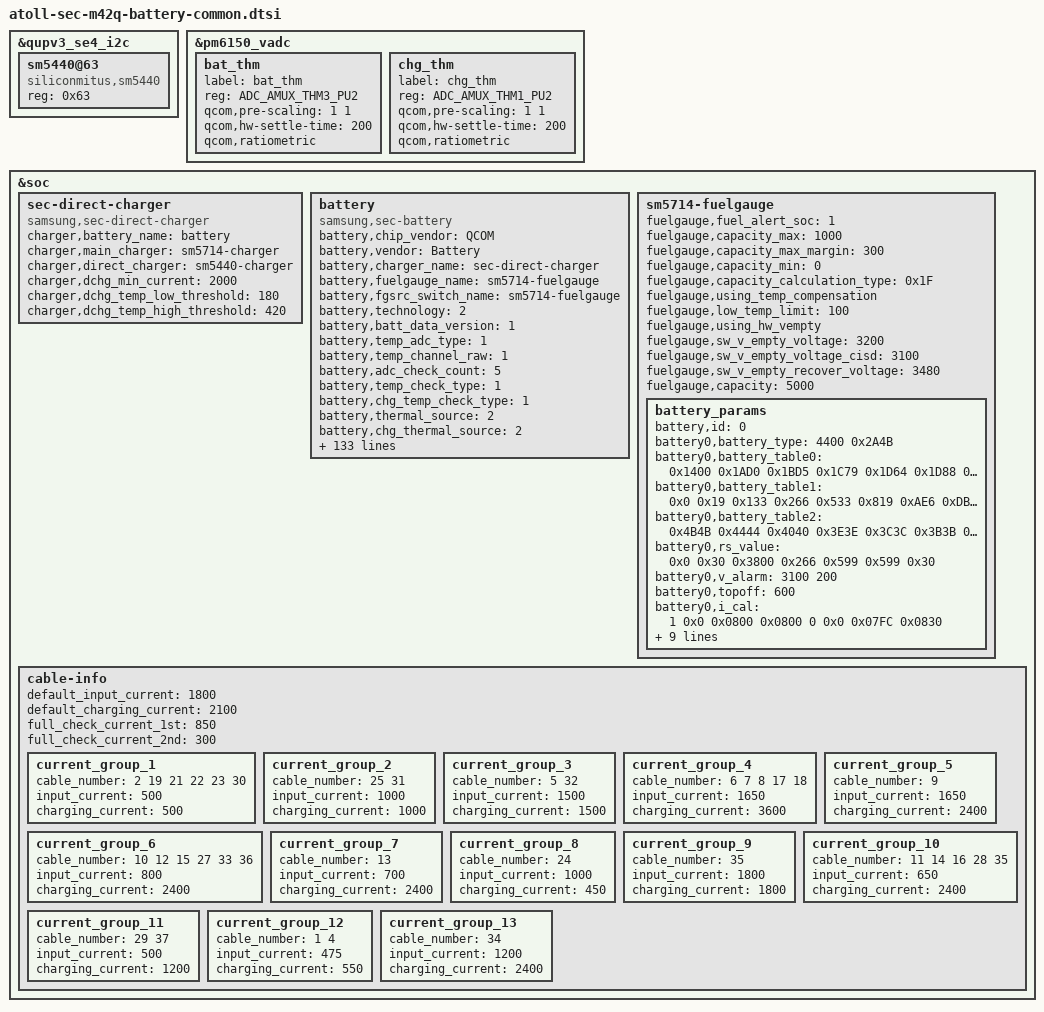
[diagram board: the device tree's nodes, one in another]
/* Copyright (c) 2016-2019, The Linux Foundation. All rights reserved.
 *
 * This program is free software; you can redistribute it and/or modify
 * it under the terms of the GNU General Public License version 2 and
 * only version 2 as published by the Free Software Foundation.
 *
 * This program is distributed in the hope that it will be useful,
 * but WITHOUT ANY WARRANTY; without even the implied warranty of
 * MERCHANTABILITY or FITNESS FOR A PARTICULAR PURPOSE.  See the
 * GNU General Public License for more details.
 */

#include <dt-bindings/iio/qcom,spmi-vadc.h>

&qupv3_se4_i2c {
	status = "okay";
	sm5440@63{
		status = "okay";
		compatible = "siliconmitus,sm5440";
		reg = <0x63>;
		pinctrl-names = "default";

	};
};

&pm6150_vadc {
	bat_thm { /* AMUX_3 */
		label = "bat_thm";
		reg = <ADC_AMUX_THM3_PU2>;
		qcom,pre-scaling = <1 1>;
		qcom,hw-settle-time = <200>;
		qcom,ratiometric;
	};
	chg_thm { /* AMUX_1 */
		label = "chg_thm";
		reg = <ADC_AMUX_THM1_PU2>;
		qcom,pre-scaling = <1 1>;
		qcom,hw-settle-time = <200>;
		qcom,ratiometric;
	};
};

&soc {

	sec-direct-charger {
		status = "okay";
		compatible = "samsung,sec-direct-charger";

		charger,battery_name = "battery";
		charger,main_charger = "sm5714-charger";
		charger,direct_charger = "sm5440-charger";

		charger,dchg_min_current = <2000>;
		charger,dchg_temp_low_threshold = <180>;
		charger,dchg_temp_high_threshold = <420>;

	};

	battery {
		pinctrl-names = "default";

		battery,chip_vendor = "QCOM";
		status = "okay";
		compatible = "samsung,sec-battery";
		battery,vendor = "Battery";
		battery,charger_name = "sec-direct-charger";
		battery,fuelgauge_name = "sm5714-fuelgauge";
		battery,fgsrc_switch_name = "sm5714-fuelgauge"; /* Fuelgauge voltage source */
		battery,technology = <2>; /* POWER_SUPPLY_TECHNOLOGY_LION */

		battery,batt_data_version = <1>;

		battery,temp_adc_type = <1>; /* SEC_BATTERY_ADC_TYPE_AP */
		battery,temp_channel_raw = <1>; /* ADC_TEMP_CHANNEL_RAW */
		battery,adc_check_count = <5>;
		battery,temp_check_type = <1>;
		battery,chg_temp_check_type = <1>;

		battery,thermal_source = <2>; /* SEC_BATTERY_THERMAL_SOURCE_ADC */
		battery,chg_thermal_source = <2>; /* SEC_BATTERY_THERMAL_SOURCE_ADC */

		battery,temp_table_adc = <2453 2872 3359 3926 4589 5313 6237
					7287 8486 9775 11135 12659 14316
					15939 17586 19166 20643 21991 23237 24313 25235 26017 26642>;
		battery,temp_table_data = <900 850 800 750 700 650 600 550 500 450
					400 350 300 250 200 150 100 50 0 (-50) (-100) (-150) (-200)>;
		battery,chg_temp_table_adc =  <1820 2174 2587 3056 3614 4233 5023
					5950 7018 8183 9450 10902 12530
					14160 15870 17555 19181 20710 22144 23412 24537 25505 26295>;
		battery,chg_temp_table_data = <900 850 800 750 700 650 600 550 500 450
			400 350 300 250 200 150 100 50 0 (-50) (-100) (-150) (-200)>;

		battery,polling_time = <10 30 30 30 3600>;

		battery,cable_check_type = <4>; /* SEC_BATTERY_CABLE_CHECK_PSY */
		battery,cable_source_type = <1>;
		battery,polling_type = <1>; /* SEC_BATTERY_MONITOR_ALARM */
		battery,monitor_initial_count = <0>;

		battery,battery_check_type = <0>; /* SEC_BATTERY_CHECK_NONE */

		battery,ovp_uvlo_check_type = <3>; /* SEC_BATTERY_OVP_UVLO_CHGPOLLING */

		battery,temp_check_count = <1>;

		battery,overheatlimit_threshold = <700>;
		battery,overheatlimit_recovery = <680>;
		battery,wire_warm_overheat_thresh = <500>;
		battery,wire_normal_warm_thresh = <420>;
		battery,wire_cool1_normal_thresh = <180>;
		battery,wire_cool2_cool1_thresh = <150>;
		battery,wire_cool3_cool2_thresh = <50>;
		battery,wire_cold_cool3_thresh = <0>;

		battery,wire_warm_current = <2093>;	/* 0.36C */
		battery,wire_cool1_current = <3600>;	/* 0.61C */
		battery,wire_cool2_current = <1390>;	/* 0.24C */
		battery,wire_cool3_current = <578>;	/* 0.1C */

		battery,low_temp_topoff = <300>;
		battery,high_temp_topoff = <300>;
		battery,low_temp_float = <4380>;
		battery,high_temp_float = <4150>;

		battery,full_check_type = <7>; /* SEC_BATTERY_FULLCHARGED_CHGPSY */
		battery,full_check_type_2nd = <7>; /* SEC_BATTERY_FULLCHARGED_CHGPSY */
		battery,full_check_count = <1>;
		battery,chg_gpio_full_check = <0>;

		battery,chg_high_temp = <500>;
		battery,chg_high_temp_recovery = <480>;
		battery,chg_input_limit_current = <1000>;
		battery,chg_charging_limit_current = <1400>;

		battery,wpc_temp_control_source = <1>;
		battery,wpc_high_temp = <380>;
		battery,wpc_high_temp_recovery = <360>;
		battery,wpc_input_limit_current = <600>;
		battery,wpc_charging_limit_current = <1000>;
		battery,wpc_temp_lcd_on_control_source = <1>;
		battery,wpc_lcd_on_high_temp = <380>;
		battery,wpc_lcd_on_high_temp_rec = <360>;
		battery,wpc_lcd_on_input_limit_current = <450>;

		battery,wpc_store_high_temp = <360>;
		battery,wpc_store_high_temp_recovery = <340>;
		battery,wpc_store_charging_limit_current = <400>;
		battery,wpc_store_lcd_on_high_temp = <360>;
		battery,wpc_store_lcd_on_high_temp_rec = <300>;
		battery,wpc_store_lcd_on_charging_limit_current = <400>;

		battery,sleep_mode_limit_current = <500>;
		battery,wc_full_input_limit_current = <100>;

		battery,mix_high_temp = <420>;
		battery,mix_high_chg_temp = <500>;
		battery,mix_high_temp_recovery = <390>;

		battery,full_condition_type = <9>;
		battery,full_condition_soc = <93>;
		battery,full_condition_vcell = <4330>;

		battery,recharge_check_count = <1>;
		battery,recharge_condition_type = <4>;
		battery,recharge_condition_soc = <98>;
		battery,recharge_condition_vcell = <4310>;

		battery,charging_total_time = <14400>;
		battery,hv_charging_total_time = <10800>;
		battery,normal_charging_total_time = <18000>;
		battery,usb_charging_total_time = <36000>;
		battery,recharging_total_time = <5400>;
		battery,charging_reset_time = <0>;

		battery,chg_float_voltage = <4380>;

		battery,pre_afc_work_delay = <2000>;
		battery,pre_wc_afc_work_delay = <4000>;
		battery,pre_afc_input_current = <500>;
		battery,pre_wc_afc_input_current = <500>;
		battery,prepare_ta_delay = <0>; /* msec */

		battery,swelling_high_rechg_voltage = <4030>;
		battery,swelling_low_rechg_voltage = <4230>;

		battery,siop_input_limit_current = <1200>;
		battery,siop_charging_limit_current = <1000>;
		battery,siop_hv_input_limit_current = <700>;
		battery,siop_hv_input_limit_current_2nd = <550>;
		battery,siop_hv_charging_limit_current = <1000>;
		battery,siop_level_20_power = <4500>;

		battery,ttf_hv_charge_current = <2450>;
		battery,ttf_dc25_charge_current = <3650>;

		battery,rp_current_rp1 = <500>;
		battery,rp_current_rp2 = <1500>;
		battery,rp_current_rp3 = <3000>;
		battery,rp_current_rdu_rp3 = <2100>;
		battery,rp_current_abnormal_rp3 = <1800>;

		battery,pd_charging_charge_power = <15000>;
		battery,max_charging_current = <3600>;

		battery,wireless_cc_cv = <85>;
		battery,wireless_otg_input_current = <900>;

		/* cycle, chg_float_voltage, recharge_condition_vcell,
		 * full_condition_vcell, full_condition_soc, step charging condition
		 */
		battery,age_data = <0 4380 4310 4280 93
			300 4360 4290 4260 92
			400 4340 4270 4240 91
			700 4320 4250 4220 90
			1000 4270 4200 4170 89>;

		battery,health_condition = <
			/* CYCLE ASOC */
			900 0  /* GOOD */
			1200 0 /* NORMAL */
			1500 0 /* AGED */
			>;

		/* step charging option */
		battery,step_charging_type = <0>;
		battery,step_charging_charge_power = <12000>;
		battery,step_charging_condition = <45 100>;
		battery,step_charging_condition_curr = <2500 2500>;
		battery,step_charging_current = <2500 2500>;
		battery,step_charging_float_voltage = <3150 4380>;

		/* direct step charging option */
		battery,dc_step_chg_type = <0xE9>;
		battery,dc_step_chg_charge_power = <22000>;
		battery,dc_step_chg_step = <3>;
		battery,dc_step_chg_cond_vol = <4090 4230 4380>; /* STEP_CHARGING_CONDITION_VOLTAGE */
		battery,dc_step_chg_cond_iin = <2050 1800 0>; /* STEP_CHARGING_CONDITION_INPUT_CURRENT */
		battery,dc_step_chg_iin_check_cnt = <3>;
		battery,dc_step_chg_cond_soc = <12 50 100>; /* STEP_CHARGING_CONDITION_SOC */
		battery,dc_step_chg_val_vfloat = <4090 4230 4380>; /* STEP_CHARGING_CONDITION_FLOAT_VOLTAGE */
		battery,dc_step_chg_val_iout = <4800 4100 3600>;
		battery,standard_curr = <3600>;
		battery,expired_time = <11100>; /* 125 + 60 minutes */
		battery,recharging_expired_time = <5400>;
		battery,battery_full_capacity = <5000>;
		battery,cisd_max_voltage_thr = <5000>; /* batttery ovp dettection voltage */

		battery,max_input_voltage = <9000>; /* mV */
		battery,max_input_current = <3000>;  /* mA */

		battery,cisd_alg_index = <8>;
		battery,ignore_cisd_index = <0 960>; /* Do not use AFC_FAIL to DROP_VALUE */
		battery,ignore_cisd_index_d = <0 120>; /* Do not use AFC_FAIL_PER_DAY to DROP_VALUE_PER_DAY */

		battery,ttf_capacity = <3300>;
		battery,cv_data = <
					2488	809	1809
					2409	812	1796
					2327	817	1769
					2272	820	1743
					2182	826	1721
					2104	830	1690
					2038	834	1670
					1950	839	1640
					1904	841	1622
					1838	845	1594
					1797	847	1576
					1749	850	1560
					1683	853	1531
					1660	855	1525
					1653	856	1515
					1615	858	1512
					1580	860	1509
					1553	861	1502
					1544	862	1483
					1520	863	1463
					1477	866	1458
					1431	868	1451
					1396	871	1424
					1347	874	1409
					1299	876	1383
					1267	878	1361
					1231	882	1332
					1202	884	1315
					1148	886	1288
					1109	889	1263
					1067	891	1243
					1031	894	1213
					1013	895	1185
					975	897	1156
					961	899	1140
					921	901	1111
					892	903	1084
					887	903	1064
					863	905	1038
					833	907	1019
					808	909	1004
					787	910	976
					764	912	946
					744	914	918
					730	915	904
					715	916	895
					693	917	864
					681	918	846
					666	920	828
					651	921	800
					640	922	783
					628	925	752
					622	926	735
					618	927	712
					600	930	697
					596	931	679
					584	933	664
					576	936	646
					577	937	627
					562	938	614
					511	948	601
					505	949	572
					493	951	553
					492	952	535
					484	953	506
					480	955	487
					474	956	464
					462	957	435
					456	958	417
					452	959	398
					446	961	380
					437	962	364
					429	964	355
					423	965	336
					422	966	329
					414	967	303
					411	968	282
					405	969	255
					397	970	242
					391	971	229
					387	972	211
					384	973	199
					372	975	191
					364	977	171
					356	978	140
					350	981	126
					340	985	107
					335	988	84
					327	991	54
					320	995	26
					313	998	13
					0	1000	0
					>;

		io-channels = <&pm6150_vadc ADC_AMUX_THM3_PU2>, <&pm6150_vadc ADC_AMUX_THM1_PU2>;
		io-channel-names = "adc-temp", "adc-chg-temp";
	};

	sm5714-fuelgauge {
		status = "okay";
		fuelgauge,fuel_alert_soc = <1>;
		fuelgauge,capacity_max = <1000>;
		fuelgauge,capacity_max_margin = <300>;
		fuelgauge,capacity_min = <0>;
		fuelgauge,capacity_calculation_type = <0x1F>;
		fuelgauge,using_temp_compensation;
		fuelgauge,low_temp_limit = <100>;
		fuelgauge,using_hw_vempty;
		fuelgauge,sw_v_empty_voltage = <3200>;
		fuelgauge,sw_v_empty_voltage_cisd = <3100>;
		fuelgauge,sw_v_empty_recover_voltage = <3480>;
		fuelgauge,capacity = <5000>;
		battery_params {
			battery,id = <0>;
			battery0,battery_type = <4400 0x2A4B>; /* batt_v_max, cap */
			battery0,battery_table0 = <
				0x1400 0x1AD0 0x1BD5 0x1C79 0x1D64 0x1D88 0x1D8F 0x1DA3
				0x1DC7 0x1DFD 0x1E29 0x1E57 0x1E74 0x1EAD 0x1EDF 0x1F1F
				0x1F67 0x1FBE 0x201F 0x2087 0x20F8 0x2168 0x2278 0x2400
				>;
			battery0,battery_table1 = <
				0x0 0x19 0x133 0x266 0x533 0x819 0xAE6 0xDB3
				0x1099 0x1633 0x1BE6 0x2199 0x274C 0x2FCC 0x3580 0x3B19
				0x3E00 0x40CC 0x4680 0x4C33 0x51CC 0x5780 0x6400 0x6419
				>;
			battery0,battery_table2 = <
				0x4B4B 0x4444 0x4040 0x3E3E 0x3C3C 0x3B3B 0x3838 0x3737
				0x3535 0x3434 0x3434 0x3333 0x3333 0x3333 0x3333 0x3232
				>;
			/* spare factor chg_factor dischg_factor manvalue */
			battery0,rs_value = <0x0 0x30 0x3800 0x266 0x599 0x599 0x30>;
			battery0,v_alarm = <3100 200>;
			battery0,topoff = <600>;
			battery0,i_cal = <1 0x0 0x0800 0x0800 0 0x0 0x07FC 0x0830>;
			battery0,v_cal = <1 0x0 0x0 1 0x0 0x0 0x0>;
			battery0,temp_std = <25>;
			battery0,tem_poff = <3400 50 3250 50>;
			battery0,aux_ctrl = <0x322 0x5800>;
			battery0,data_ver = <2>;
			battery0,v_max_table = <0x2278 0x2259 0x223A 0x221B 0x21C7>;
			battery0,q_max_table = <0x2A4B 0x2998 0x28E5 0x2832 0x2673>;
		};
	};

	/* sec_battery_cable
	 *   0	UNKNOWN,
	 *   1	NONE,
	 *   2	PREPARE_TA,
	 *   3	TA,
	 *   4	USB,
	 *   5	USB_CDP,
	 *   6	9V_TA,
	 *   7	9V_ERR,
	 *   8	9V_UNKNOWN,
	 *   9	12V_TA,
	 *  10	WIRELESS,
	 *  11	HV_WIRELESS,
	 *  12	PMA_WIRELESS,
	 *  13	WIRELESS_PACK,
	 *  14	CABLE_WIRELESS_HV_PACK,
	 *  15	WIRELESS_STAND,
	 *  16	WIRELESS_HV_STAND,
	 *  17	QC20,
	 *  18	QC30,
	 *  19	PDIC,
	 *  20	UARTOFF,
	 *  21	OTG,
	 *  22	LAN_HUB,
	 *  23	POWER_SHARING,
	 *  24	HMT_CONNECTED,
	 *  25	HMT_CHARGE,
	 *  26	HV_TA_CHG_LIMIT,
	 *  27	WIRELESS_VEHICLE,
	 *  28	WIRELESS_HV_VEHICLE,
	 *  29	PREPARE_WIRELESS_HV,
	 *  30  TIMEOUT,
	 *  31  SMART_OTG,
	 *  32  SMART_NOTG,
	 *  33  WIRELESS_TX,
	 *  34	HV_WIRELESS_20,
	 *  35	HV_WIRELESS_20_LIMIT,
	 *  36	WIRELESS_FAKE,
	 *  37  PREPARE_WIRELESS_20,
	 *  38	CABLE_PDIC_APDO,
	 *  39	CABLE_MAX,
	 */
	cable-info {
		default_input_current = <1800>;
		default_charging_current = <2100>;
		full_check_current_1st = <850>;
		full_check_current_2nd = <300>;

		current_group_1 {
			cable_number = <2 19 21 22 23 30>;
			input_current = <500>;
			charging_current = <500>;
		};
		current_group_2 {
			cable_number = <25 31>;
			input_current = <1000>;
			charging_current = <1000>;
		};
		current_group_3 {
			cable_number = <5 32>;
			input_current = <1500>;
			charging_current = <1500>;
		};
		current_group_4 {
			cable_number = <6 7 8 17 18>;
			input_current = <1650>;
			charging_current = <3600>;
		};
		current_group_5 {
			cable_number = <9>;
			input_current = <1650>;
			charging_current = <2400>;
		};
		current_group_6 {
			cable_number = <10 12 15 27 33 36>;
			input_current = <800>;
			charging_current = <2400>;
		};
		current_group_7 {
			cable_number = <13>;
			input_current = <700>;
			charging_current = <2400>;
		};
		current_group_8 {
			cable_number = <24>;
			input_current = <1000>;
			charging_current = <450>;
		};
		current_group_9 {
			cable_number = <35>;
			input_current = <1800>;
			charging_current = <1800>;
		};
		current_group_10 {
			cable_number = <11 14 16 28 35>;
			input_current = <650>;
			charging_current = <2400>;
		};
		current_group_11 {
			cable_number = <29 37>;
			input_current = <500>;
			charging_current = <1200>;
		};
		current_group_12 {
			cable_number = <1 4>;
			input_current = <475>;
			charging_current = <550>;
		};
		current_group_13 {
			cable_number = <34>;
			input_current = <1200>;
			charging_current = <2400>;
		};
	};
};
